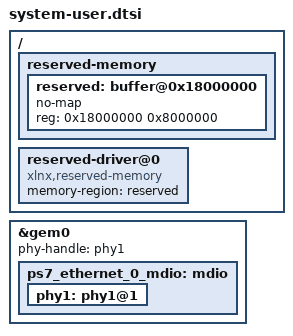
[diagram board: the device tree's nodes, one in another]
/include/ "system-conf.dtsi"
/ {
	reserved-memory {
		#address-cells = <1>;
		#size-cells = <1>;
		ranges;
		reserved: buffer@0x18000000 {
			no-map;
			reg = <0x18000000 0x8000000>;
		};
	};

	reserved-driver@0 {
		compatible = "xlnx,reserved-memory";
		memory-region = <&reserved>;
	};
};

&gem0 {
	phy-handle = <&phy1>;
	ps7_ethernet_0_mdio: mdio {
		phy1: phy1@1 {
			device_type = "ethernet-phy";
		};
	};
};
